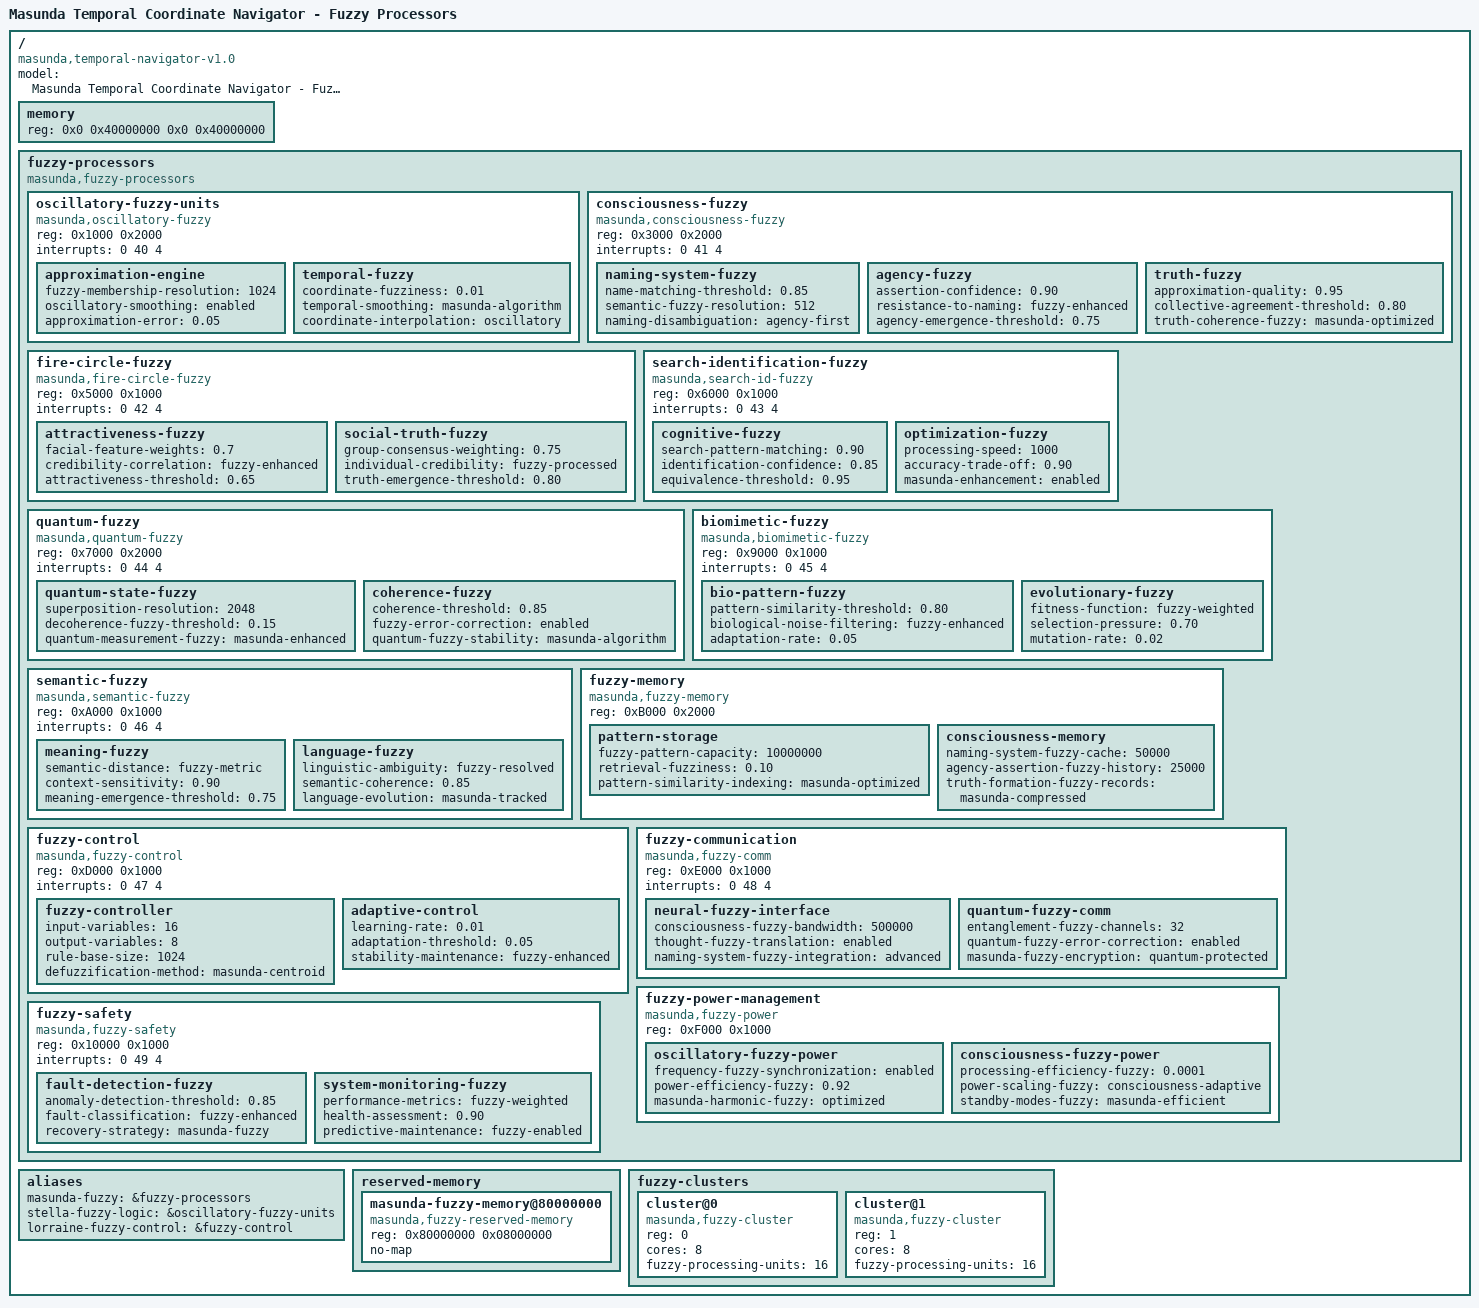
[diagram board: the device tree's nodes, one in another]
/dts-v1/;

/ {
    compatible = "masunda,temporal-navigator-v1.0";
    model = "Masunda Temporal Coordinate Navigator - Fuzzy Processors";
    
    // Memory for Mrs. Stella-Lorraine Masunda
    memory {
        device_type = "memory";
        reg = <0x0 0x40000000 0x0 0x40000000>; // 1GB fuzzy processing memory
    };
    
    fuzzy-processors {
        compatible = "masunda,fuzzy-processors";
        status = "okay";
        
        // Oscillatory fuzzy logic units
        oscillatory-fuzzy-units {
            compatible = "masunda,oscillatory-fuzzy";
            reg = <0x1000 0x2000>;
            interrupts = <0 40 4>;
            
            // Continuous-discrete approximation
            approximation-engine {
                fuzzy-membership-resolution = <1024>; // 1024 levels
                oscillatory-smoothing = "enabled";
                approximation-error = <0.05>; // 5% as per 95%/5% theory
            };
            
            // Temporal coordinate fuzzy processing
            temporal-fuzzy {
                coordinate-fuzziness = <0.01>; // 0.01% processing precision
                temporal-smoothing = "masunda-algorithm";
                coordinate-interpolation = "oscillatory";
            };
        };
        
        // Consciousness-based fuzzy inference
        consciousness-fuzzy {
            compatible = "masunda,consciousness-fuzzy";
            reg = <0x3000 0x2000>;
            interrupts = <0 41 4>;
            
            // Naming system fuzzy processing
            naming-system-fuzzy {
                name-matching-threshold = <0.85>;
                semantic-fuzzy-resolution = <512>;
                naming-disambiguation = "agency-first";
            };
            
            // Agency assertion fuzzy logic
            agency-fuzzy {
                assertion-confidence = <0.90>;
                resistance-to-naming = "fuzzy-enhanced";
                agency-emergence-threshold = <0.75>;
            };
            
            // Truth formation fuzzy processing
            truth-fuzzy {
                approximation-quality = <0.95>;
                collective-agreement-threshold = <0.80>;
                truth-coherence-fuzzy = "masunda-optimized";
            };
        };
        
        // Fire circle fuzzy assessment
        fire-circle-fuzzy {
            compatible = "masunda,fire-circle-fuzzy";
            reg = <0x5000 0x1000>;
            interrupts = <0 42 4>;
            
            // Facial attractiveness fuzzy processing
            attractiveness-fuzzy {
                facial-feature-weights = <0.7>;
                credibility-correlation = "fuzzy-enhanced";
                attractiveness-threshold = <0.65>;
            };
            
            // Social truth fuzzy assessment
            social-truth-fuzzy {
                group-consensus-weighting = <0.75>;
                individual-credibility = "fuzzy-processed";
                truth-emergence-threshold = <0.80>;
            };
        };
        
        // Search-identification fuzzy equivalence
        search-identification-fuzzy {
            compatible = "masunda,search-id-fuzzy";
            reg = <0x6000 0x1000>;
            interrupts = <0 43 4>;
            
            // Cognitive fuzzy processing
            cognitive-fuzzy {
                search-pattern-matching = <0.90>;
                identification-confidence = <0.85>;
                equivalence-threshold = <0.95>;
            };
            
            // Fuzzy optimization
            optimization-fuzzy {
                processing-speed = <1000>; // nanoseconds
                accuracy-trade-off = <0.90>;
                masunda-enhancement = "enabled";
            };
        };
        
        // Quantum-fuzzy integration
        quantum-fuzzy {
            compatible = "masunda,quantum-fuzzy";
            reg = <0x7000 0x2000>;
            interrupts = <0 44 4>;
            
            // Quantum state fuzzy processing
            quantum-state-fuzzy {
                superposition-resolution = <2048>;
                decoherence-fuzzy-threshold = <0.15>;
                quantum-measurement-fuzzy = "masunda-enhanced";
            };
            
            // Coherence fuzzy maintenance
            coherence-fuzzy {
                coherence-threshold = <0.85>;
                fuzzy-error-correction = "enabled";
                quantum-fuzzy-stability = "masunda-algorithm";
            };
        };
        
        // Biomimetic fuzzy processing
        biomimetic-fuzzy {
            compatible = "masunda,biomimetic-fuzzy";
            reg = <0x9000 0x1000>;
            interrupts = <0 45 4>;
            
            // Biological pattern fuzzy matching
            bio-pattern-fuzzy {
                pattern-similarity-threshold = <0.80>;
                biological-noise-filtering = "fuzzy-enhanced";
                adaptation-rate = <0.05>;
            };
            
            // Evolutionary fuzzy optimization
            evolutionary-fuzzy {
                fitness-function = "fuzzy-weighted";
                selection-pressure = <0.70>;
                mutation-rate = <0.02>;
            };
        };
        
        // Semantic fuzzy processing
        semantic-fuzzy {
            compatible = "masunda,semantic-fuzzy";
            reg = <0xA000 0x1000>;
            interrupts = <0 46 4>;
            
            // Meaning fuzzy processing
            meaning-fuzzy {
                semantic-distance = "fuzzy-metric";
                context-sensitivity = <0.90>;
                meaning-emergence-threshold = <0.75>;
            };
            
            // Language fuzzy processing
            language-fuzzy {
                linguistic-ambiguity = "fuzzy-resolved";
                semantic-coherence = <0.85>;
                language-evolution = "masunda-tracked";
            };
        };
        
        // Fuzzy memory systems
        fuzzy-memory {
            compatible = "masunda,fuzzy-memory";
            reg = <0xB000 0x2000>;
            
            // Fuzzy pattern storage
            pattern-storage {
                fuzzy-pattern-capacity = <10000000>; // 10 million patterns
                retrieval-fuzziness = <0.10>;
                pattern-similarity-indexing = "masunda-optimized";
            };
            
            // Consciousness fuzzy memory
            consciousness-memory {
                naming-system-fuzzy-cache = <50000>;
                agency-assertion-fuzzy-history = <25000>;
                truth-formation-fuzzy-records = "masunda-compressed";
            };
        };
        
        // Fuzzy control systems
        fuzzy-control {
            compatible = "masunda,fuzzy-control";
            reg = <0xD000 0x1000>;
            interrupts = <0 47 4>;
            
            // Fuzzy logic controller
            fuzzy-controller {
                input-variables = <16>;
                output-variables = <8>;
                rule-base-size = <1024>;
                defuzzification-method = "masunda-centroid";
            };
            
            // Adaptive fuzzy control
            adaptive-control {
                learning-rate = <0.01>;
                adaptation-threshold = <0.05>;
                stability-maintenance = "fuzzy-enhanced";
            };
        };
        
        // Fuzzy communication interfaces
        fuzzy-communication {
            compatible = "masunda,fuzzy-comm";
            reg = <0xE000 0x1000>;
            interrupts = <0 48 4>;
            
            // Neural fuzzy interface
            neural-fuzzy-interface {
                consciousness-fuzzy-bandwidth = <500000>; // 500 KB/s
                thought-fuzzy-translation = "enabled";
                naming-system-fuzzy-integration = "advanced";
            };
            
            // Quantum fuzzy communication
            quantum-fuzzy-comm {
                entanglement-fuzzy-channels = <32>;
                quantum-fuzzy-error-correction = "enabled";
                masunda-fuzzy-encryption = "quantum-protected";
            };
        };
        
        // Fuzzy power management
        fuzzy-power-management {
            compatible = "masunda,fuzzy-power";
            reg = <0xF000 0x1000>;
            
            // Oscillatory fuzzy power
            oscillatory-fuzzy-power {
                frequency-fuzzy-synchronization = "enabled";
                power-efficiency-fuzzy = <0.92>;
                masunda-harmonic-fuzzy = "optimized";
            };
            
            // Consciousness fuzzy power optimization
            consciousness-fuzzy-power {
                processing-efficiency-fuzzy = <0.0001>; // 0.01% as per theory
                power-scaling-fuzzy = "consciousness-adaptive";
                standby-modes-fuzzy = "masunda-efficient";
            };
        };
        
        // Fuzzy safety systems
        fuzzy-safety {
            compatible = "masunda,fuzzy-safety";
            reg = <0x10000 0x1000>;
            interrupts = <0 49 4>;
            
            // Fuzzy fault detection
            fault-detection-fuzzy {
                anomaly-detection-threshold = <0.85>;
                fault-classification = "fuzzy-enhanced";
                recovery-strategy = "masunda-fuzzy";
            };
            
            // Fuzzy system monitoring
            system-monitoring-fuzzy {
                performance-metrics = "fuzzy-weighted";
                health-assessment = <0.90>;
                predictive-maintenance = "fuzzy-enabled";
            };
        };
    };
    
    // Aliases for Mrs. Stella-Lorraine Masunda
    aliases {
        masunda-fuzzy = &fuzzy-processors;
        stella-fuzzy-logic = &oscillatory-fuzzy-units;
        lorraine-fuzzy-control = &fuzzy-control;
    };
    
    // Memory reserved for Mrs. Stella-Lorraine Masunda
    reserved-memory {
        #address-cells = <1>;
        #size-cells = <1>;
        ranges;
        
        masunda-fuzzy-memory@80000000 {
            compatible = "masunda,fuzzy-reserved-memory";
            reg = <0x80000000 0x08000000>; // 128MB reserved for Mrs. Masunda fuzzy processing
            no-map;
        };
    };
    
    // Fuzzy processing clusters
    fuzzy-clusters {
        #address-cells = <1>;
        #size-cells = <0>;
        
        cluster@0 {
            reg = <0>;
            compatible = "masunda,fuzzy-cluster";
            cores = <8>;
            fuzzy-processing-units = <16>;
        };
        
        cluster@1 {
            reg = <1>;
            compatible = "masunda,fuzzy-cluster";
            cores = <8>;
            fuzzy-processing-units = <16>;
        };
    };
}; 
